VERSION ""

NS_ :

BS_:

BU_: XXX

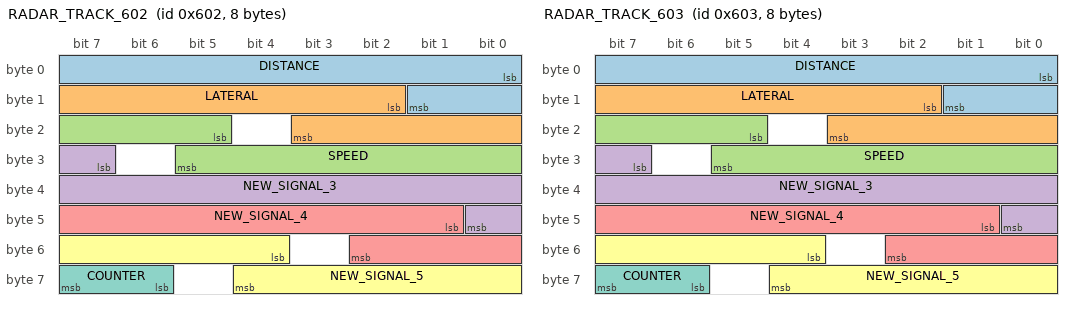
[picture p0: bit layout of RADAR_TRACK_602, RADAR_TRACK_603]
BO_ 1538 RADAR_TRACK_602: 8 RADAR
 SG_ DISTANCE : 0|10@1+ (0.1,0) [-128|127] "" XXX
 SG_ LATERAL : 10|10@1- (1,0) [0|511] "" XXX
 SG_ SPEED : 21|9@1- (1,0) [0|63] "" XXX
 SG_ NEW_SIGNAL_3 : 31|10@1+ (1,0) [0|511] "" XXX
 SG_ NEW_SIGNAL_4 : 41|10@1- (1,0) [0|1023] "" XXX
 SG_ NEW_SIGNAL_5 : 52|9@1- (1,0) [0|15] "" XXX
 SG_ COUNTER : 62|2@1+ (1,0) [0|3] "" XXX

BO_ 1539 RADAR_TRACK_603: 8 RADAR
 SG_ DISTANCE : 0|10@1+ (0.1,0) [-128|127] "" XXX
 SG_ LATERAL : 10|10@1- (1,0) [0|511] "" XXX
 SG_ SPEED : 21|9@1- (1,0) [0|63] "" XXX
 SG_ NEW_SIGNAL_3 : 31|10@1+ (1,0) [0|511] "" XXX
 SG_ NEW_SIGNAL_4 : 41|10@1- (1,0) [0|1023] "" XXX
 SG_ NEW_SIGNAL_5 : 52|9@1- (1,0) [0|15] "" XXX
 SG_ COUNTER : 62|2@1+ (1,0) [0|3] "" XXX

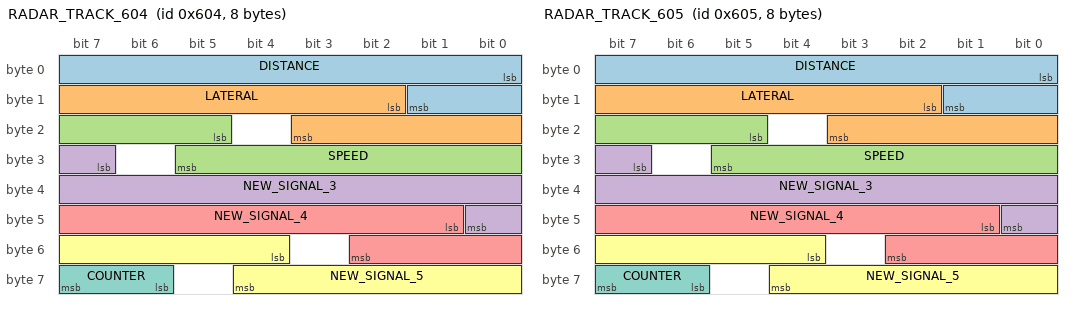
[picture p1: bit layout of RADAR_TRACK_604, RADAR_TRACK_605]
BO_ 1540 RADAR_TRACK_604: 8 RADAR
 SG_ DISTANCE : 0|10@1+ (0.1,0) [-128|127] "" XXX
 SG_ LATERAL : 10|10@1- (1,0) [0|511] "" XXX
 SG_ SPEED : 21|9@1- (1,0) [0|63] "" XXX
 SG_ NEW_SIGNAL_3 : 31|10@1+ (1,0) [0|511] "" XXX
 SG_ NEW_SIGNAL_4 : 41|10@1- (1,0) [0|1023] "" XXX
 SG_ NEW_SIGNAL_5 : 52|9@1- (1,0) [0|15] "" XXX
 SG_ COUNTER : 62|2@1+ (1,0) [0|3] "" XXX

BO_ 1541 RADAR_TRACK_605: 8 RADAR
 SG_ DISTANCE : 0|10@1+ (0.1,0) [-128|127] "" XXX
 SG_ LATERAL : 10|10@1- (1,0) [0|511] "" XXX
 SG_ SPEED : 21|9@1- (1,0) [0|63] "" XXX
 SG_ NEW_SIGNAL_3 : 31|10@1+ (1,0) [0|511] "" XXX
 SG_ NEW_SIGNAL_4 : 41|10@1- (1,0) [0|1023] "" XXX
 SG_ NEW_SIGNAL_5 : 52|9@1- (1,0) [0|15] "" XXX
 SG_ COUNTER : 62|2@1+ (1,0) [0|3] "" XXX

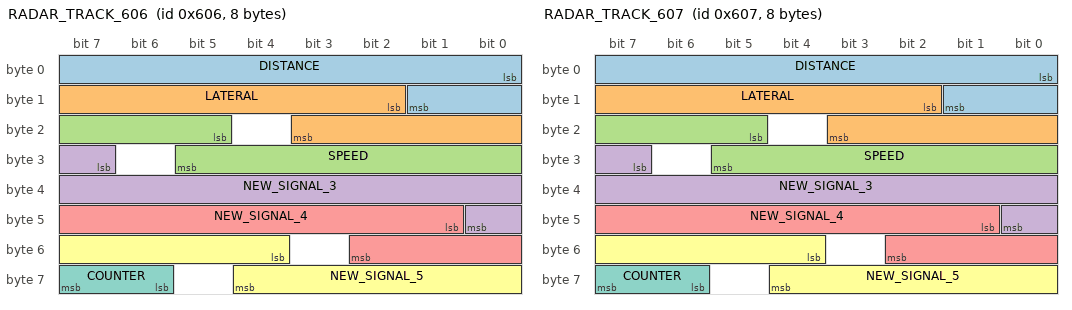
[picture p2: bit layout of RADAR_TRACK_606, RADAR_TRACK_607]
BO_ 1542 RADAR_TRACK_606: 8 RADAR
 SG_ DISTANCE : 0|10@1+ (0.1,0) [-128|127] "" XXX
 SG_ LATERAL : 10|10@1- (1,0) [0|511] "" XXX
 SG_ SPEED : 21|9@1- (1,0) [0|63] "" XXX
 SG_ NEW_SIGNAL_3 : 31|10@1+ (1,0) [0|511] "" XXX
 SG_ NEW_SIGNAL_4 : 41|10@1- (1,0) [0|1023] "" XXX
 SG_ NEW_SIGNAL_5 : 52|9@1- (1,0) [0|15] "" XXX
 SG_ COUNTER : 62|2@1+ (1,0) [0|3] "" XXX

BO_ 1543 RADAR_TRACK_607: 8 RADAR
 SG_ DISTANCE : 0|10@1+ (0.1,0) [-128|127] "" XXX
 SG_ LATERAL : 10|10@1- (1,0) [0|511] "" XXX
 SG_ SPEED : 21|9@1- (1,0) [0|63] "" XXX
 SG_ NEW_SIGNAL_3 : 31|10@1+ (1,0) [0|511] "" XXX
 SG_ NEW_SIGNAL_4 : 41|10@1- (1,0) [0|1023] "" XXX
 SG_ NEW_SIGNAL_5 : 52|9@1- (1,0) [0|15] "" XXX
 SG_ COUNTER : 62|2@1+ (1,0) [0|3] "" XXX

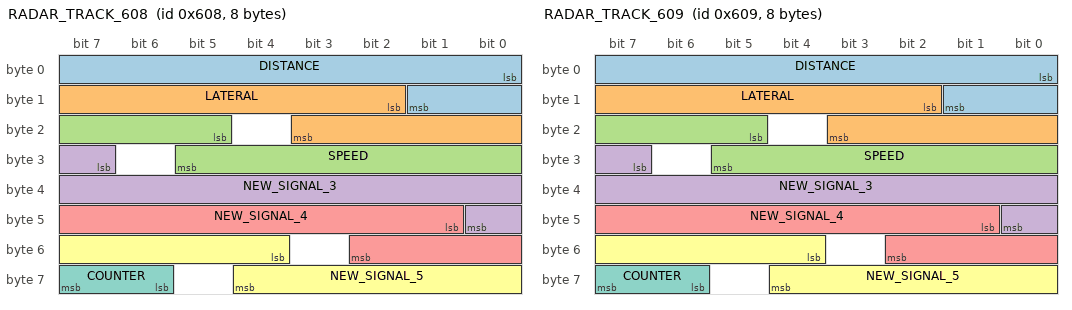
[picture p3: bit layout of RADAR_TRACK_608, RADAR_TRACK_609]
BO_ 1544 RADAR_TRACK_608: 8 RADAR
 SG_ DISTANCE : 0|10@1+ (0.1,0) [-128|127] "" XXX
 SG_ LATERAL : 10|10@1- (1,0) [0|511] "" XXX
 SG_ SPEED : 21|9@1- (1,0) [0|63] "" XXX
 SG_ NEW_SIGNAL_3 : 31|10@1+ (1,0) [0|511] "" XXX
 SG_ NEW_SIGNAL_4 : 41|10@1- (1,0) [0|1023] "" XXX
 SG_ NEW_SIGNAL_5 : 52|9@1- (1,0) [0|15] "" XXX
 SG_ COUNTER : 62|2@1+ (1,0) [0|3] "" XXX

BO_ 1545 RADAR_TRACK_609: 8 RADAR
 SG_ DISTANCE : 0|10@1+ (0.1,0) [-128|127] "" XXX
 SG_ LATERAL : 10|10@1- (1,0) [0|511] "" XXX
 SG_ SPEED : 21|9@1- (1,0) [0|63] "" XXX
 SG_ NEW_SIGNAL_3 : 31|10@1+ (1,0) [0|511] "" XXX
 SG_ NEW_SIGNAL_4 : 41|10@1- (1,0) [0|1023] "" XXX
 SG_ NEW_SIGNAL_5 : 52|9@1- (1,0) [0|15] "" XXX
 SG_ COUNTER : 62|2@1+ (1,0) [0|3] "" XXX

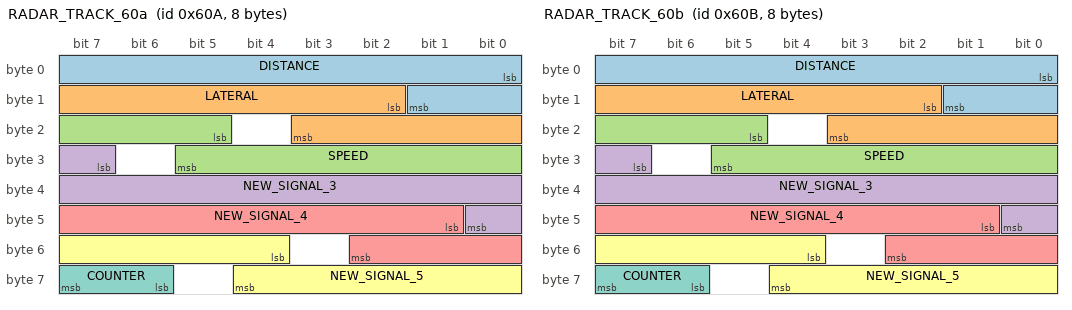
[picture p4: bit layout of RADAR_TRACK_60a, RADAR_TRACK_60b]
BO_ 1546 RADAR_TRACK_60a: 8 RADAR
 SG_ DISTANCE : 0|10@1+ (0.1,0) [-128|127] "" XXX
 SG_ LATERAL : 10|10@1- (1,0) [0|511] "" XXX
 SG_ SPEED : 21|9@1- (1,0) [0|63] "" XXX
 SG_ NEW_SIGNAL_3 : 31|10@1+ (1,0) [0|511] "" XXX
 SG_ NEW_SIGNAL_4 : 41|10@1- (1,0) [0|1023] "" XXX
 SG_ NEW_SIGNAL_5 : 52|9@1- (1,0) [0|15] "" XXX
 SG_ COUNTER : 62|2@1+ (1,0) [0|3] "" XXX

BO_ 1547 RADAR_TRACK_60b: 8 RADAR
 SG_ DISTANCE : 0|10@1+ (0.1,0) [-128|127] "" XXX
 SG_ LATERAL : 10|10@1- (1,0) [0|511] "" XXX
 SG_ SPEED : 21|9@1- (1,0) [0|63] "" XXX
 SG_ NEW_SIGNAL_3 : 31|10@1+ (1,0) [0|511] "" XXX
 SG_ NEW_SIGNAL_4 : 41|10@1- (1,0) [0|1023] "" XXX
 SG_ NEW_SIGNAL_5 : 52|9@1- (1,0) [0|15] "" XXX
 SG_ COUNTER : 62|2@1+ (1,0) [0|3] "" XXX

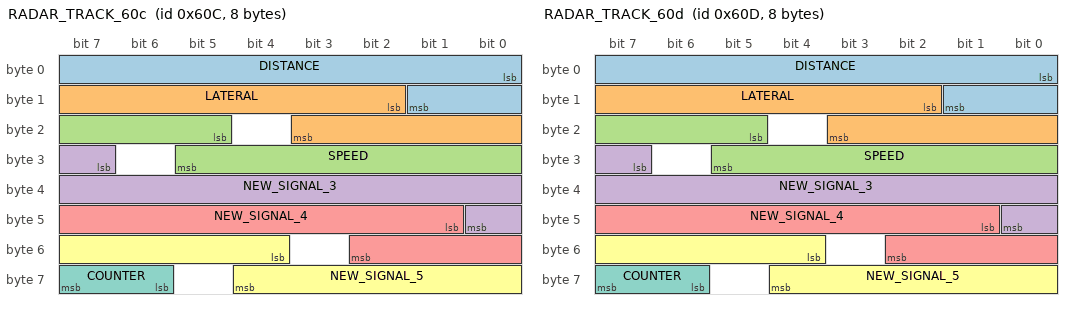
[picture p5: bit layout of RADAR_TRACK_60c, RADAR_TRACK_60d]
BO_ 1548 RADAR_TRACK_60c: 8 RADAR
 SG_ DISTANCE : 0|10@1+ (0.1,0) [-128|127] "" XXX
 SG_ LATERAL : 10|10@1- (1,0) [0|511] "" XXX
 SG_ SPEED : 21|9@1- (1,0) [0|63] "" XXX
 SG_ NEW_SIGNAL_3 : 31|10@1+ (1,0) [0|511] "" XXX
 SG_ NEW_SIGNAL_4 : 41|10@1- (1,0) [0|1023] "" XXX
 SG_ NEW_SIGNAL_5 : 52|9@1- (1,0) [0|15] "" XXX
 SG_ COUNTER : 62|2@1+ (1,0) [0|3] "" XXX

BO_ 1549 RADAR_TRACK_60d: 8 RADAR
 SG_ DISTANCE : 0|10@1+ (0.1,0) [-128|127] "" XXX
 SG_ LATERAL : 10|10@1- (1,0) [0|511] "" XXX
 SG_ SPEED : 21|9@1- (1,0) [0|63] "" XXX
 SG_ NEW_SIGNAL_3 : 31|10@1+ (1,0) [0|511] "" XXX
 SG_ NEW_SIGNAL_4 : 41|10@1- (1,0) [0|1023] "" XXX
 SG_ NEW_SIGNAL_5 : 52|9@1- (1,0) [0|15] "" XXX
 SG_ COUNTER : 62|2@1+ (1,0) [0|3] "" XXX

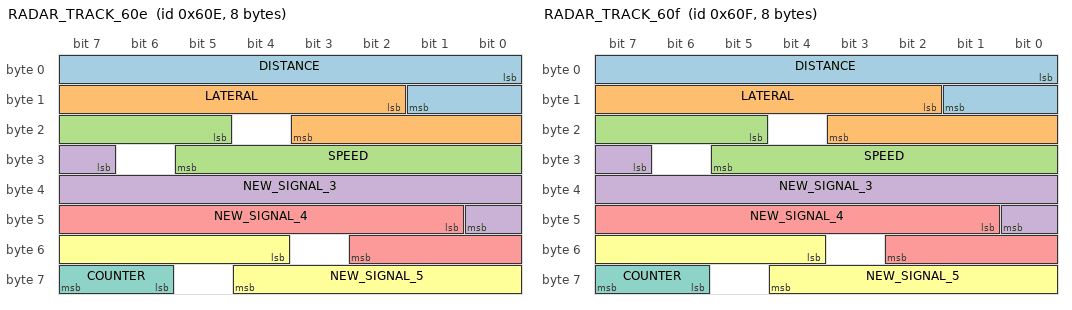
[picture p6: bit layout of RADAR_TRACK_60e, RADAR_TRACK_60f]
BO_ 1550 RADAR_TRACK_60e: 8 RADAR
 SG_ DISTANCE : 0|10@1+ (0.1,0) [-128|127] "" XXX
 SG_ LATERAL : 10|10@1- (1,0) [0|511] "" XXX
 SG_ SPEED : 21|9@1- (1,0) [0|63] "" XXX
 SG_ NEW_SIGNAL_3 : 31|10@1+ (1,0) [0|511] "" XXX
 SG_ NEW_SIGNAL_4 : 41|10@1- (1,0) [0|1023] "" XXX
 SG_ NEW_SIGNAL_5 : 52|9@1- (1,0) [0|15] "" XXX
 SG_ COUNTER : 62|2@1+ (1,0) [0|3] "" XXX

BO_ 1551 RADAR_TRACK_60f: 8 RADAR
 SG_ DISTANCE : 0|10@1+ (0.1,0) [-128|127] "" XXX
 SG_ LATERAL : 10|10@1- (1,0) [0|511] "" XXX
 SG_ SPEED : 21|9@1- (1,0) [0|63] "" XXX
 SG_ NEW_SIGNAL_3 : 31|10@1+ (1,0) [0|511] "" XXX
 SG_ NEW_SIGNAL_4 : 41|10@1- (1,0) [0|1023] "" XXX
 SG_ NEW_SIGNAL_5 : 52|9@1- (1,0) [0|15] "" XXX
 SG_ COUNTER : 62|2@1+ (1,0) [0|3] "" XXX

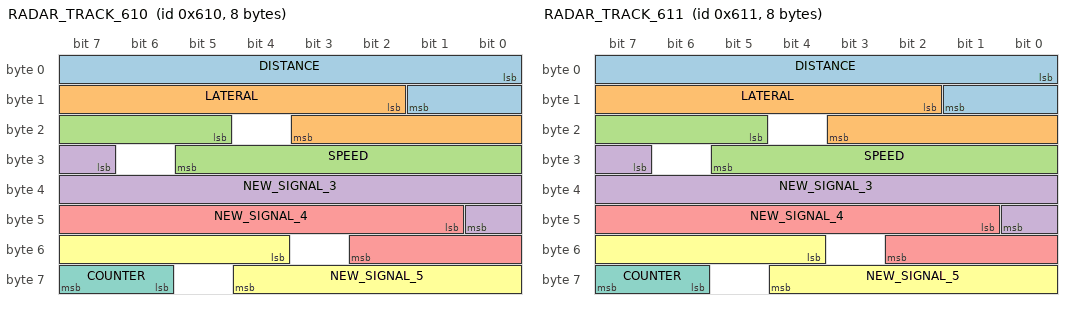
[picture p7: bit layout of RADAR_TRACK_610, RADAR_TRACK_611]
BO_ 1552 RADAR_TRACK_610: 8 RADAR
 SG_ DISTANCE : 0|10@1+ (0.1,0) [-128|127] "" XXX
 SG_ LATERAL : 10|10@1- (1,0) [0|511] "" XXX
 SG_ SPEED : 21|9@1- (1,0) [0|63] "" XXX
 SG_ NEW_SIGNAL_3 : 31|10@1+ (1,0) [0|511] "" XXX
 SG_ NEW_SIGNAL_4 : 41|10@1- (1,0) [0|1023] "" XXX
 SG_ NEW_SIGNAL_5 : 52|9@1- (1,0) [0|15] "" XXX
 SG_ COUNTER : 62|2@1+ (1,0) [0|3] "" XXX

BO_ 1553 RADAR_TRACK_611: 8 RADAR
 SG_ DISTANCE : 0|10@1+ (0.1,0) [-128|127] "" XXX
 SG_ LATERAL : 10|10@1- (1,0) [0|511] "" XXX
 SG_ SPEED : 21|9@1- (1,0) [0|63] "" XXX
 SG_ NEW_SIGNAL_3 : 31|10@1+ (1,0) [0|511] "" XXX
 SG_ NEW_SIGNAL_4 : 41|10@1- (1,0) [0|1023] "" XXX
 SG_ NEW_SIGNAL_5 : 52|9@1- (1,0) [0|15] "" XXX
 SG_ COUNTER : 62|2@1+ (1,0) [0|3] "" XXX
